# RasbperryPi register map
File version: 1
Registers are 32-bit, read-write, reset 0x0 unless marked. A register's access mark holds for its fields unless they carry their own. Offsets are from the block's base; [hi:lo] are bit positions; {n}, {i} and the like mark numbered series.

## CAM0 — Derived from cam0_a0.h apb_id: 0x7563616D
Base 0x7E800000
Same registers: CAM1 0x7E801000, CAM1 0x7E801000
0x00 CTL
  [31:0] data
0x00 ICTL
  [31:0] data
0x00 DCS
  [31:0] data
0x04 STA
  [31:0] data
0x04 ISTA
  [31:0] data
0x04 DBSA
  [31:0] data
0x08 ANA
  [31:0] data
0x08 IDI
  [31:0] data
0x08 DBEA
  [31:0] data
0x08 DBWP
  [31:0] data
0x0C PRI
  [31:0] data
0x0C IPIPE
  [31:0] data
0x10 CLK
  [31:0] data
0x10 IBSA
  [31:0] data
{0x14+4i} DAT{i} (i=0..3)
  [31:0] data
0x14 IBEA
  [31:0] data
0x18 IBLS
  [31:0] data
0x1C IBWP
  [31:0] data
0x20 IHWIN
  [31:0] data
0x24 CMP0
  [31:0] data
0x24 IHSTA
  [31:0] data
0x28 CMP1
  [31:0] data
0x28 IVWIN
  [31:0] data
0x2C CAP0
  [31:0] data
0x2C IVSTA
  [31:0] data
0x30 CAP1
  [31:0] data
{0xF0+4i} DBG{i} (i=0..2)
  [31:0] data

## CCP — Derived from camccp.h apb_id: 0x63637032
Base 0x7E801000
Same registers: ISP 0x7EA00000, H264 0x7F000000
0x00 RC reset not defined
  [31:0] data

## CCP2TX — Derived from ccp2tx.h apb_id: 0x63637032
Base 0x7E001000
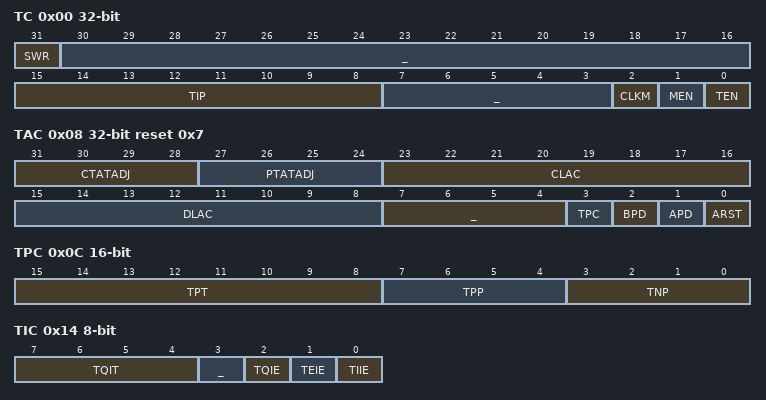
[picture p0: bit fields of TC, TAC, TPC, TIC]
0x00 TC
  [31] SWR, [30:16] _, [15:8] TIP, [7:3] _, [2] CLKM, [1] MEN, [0] TEN
0x04 TS 20-bit
  [19] TQI, [18] TEI, [17] TII, [16] IS, [15:13] _, [12:8] TQL, [7] _, [6] TFP, [5] TFF, [4] TFE, [3] TUE, [2] ARE, [1] IEB, [0] TXB
0x08 TAC reset 0x7
  [31:28] CTATADJ, [27:24] PTATADJ, [23:16] CLAC, [15:8] DLAC, [7:4] _, [3] TPC, [2] BPD, [1] APD, [0] ARST
0x0C TPC 16-bit
  [15:8] TPT, [7:4] TPP, [3:0] TNP
0x10 TSC 4-bit reset 0x2
  [3:0] TSM
0x14 TIC 8-bit
  [7:4] TQIT, [3] _, [2] TQIE, [1] TEIE, [0] TIIE
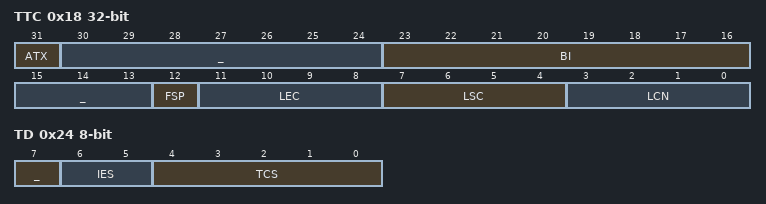
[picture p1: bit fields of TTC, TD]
0x18 TTC
  [31] ATX, [30:24] _, [23:16] BI, [15:13] _, [12] FSP, [11:8] LEC, [7:4] LSC, [3:0] LCN
0x1C TBA 30-bit
  [29:0] ADDR
0x20 TDL 30-bit
  [29:0] LEN
0x24 TD 8-bit reset not defined
  [7] _, [6:5] IES, [4:0] TCS
0x28 TSPARE reset not defined
  [31:0] data
